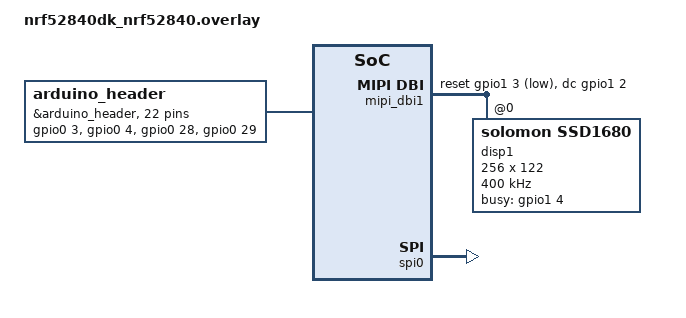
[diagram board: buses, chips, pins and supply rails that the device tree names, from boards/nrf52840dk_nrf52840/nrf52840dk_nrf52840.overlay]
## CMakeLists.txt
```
cmake_minimum_required(VERSION 3.20.0)
find_package(Zephyr REQUIRED HINTS $ENV{ZEPHYR_BASE})

project(Attempt6WS)

file(GLOB FONT_SOURCES fonts/*.c)

target_sources(app PRIVATE
    src/main.c
    src/fonts5x7.c
    src/fonts_8x12_montserrat.c
    src/mab_labs.c
    src/my_image.c
    ${FONT_SOURCES}
)

target_include_directories(app PRIVATE
  include
)
```

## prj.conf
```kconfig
CONFIG_DISPLAY=y
CONFIG_SSD16XX=y

CONFIG_SPI=y
CONFIG_SPI_NRFX=y

CONFIG_GPIO=y
CONFIG_GPIO_NRFX=y

CONFIG_LOG=y
CONFIG_DISPLAY_LOG_LEVEL_DBG=y
# CONFIG_LOG_BUFFER_SIZE=8192
# CONFIG_LOG_MODE_IMMEDIATE=y


CONFIG_SERIAL=y
CONFIG_UART_CONSOLE=y
CONFIG_CONSOLE=y

# Optional debug
# CONFIG_SSD16XX_LOG_LEVEL_DBG=y
# CONFIG_MIPI_DBI_LOG_LEVEL_DBG=y
# CONFIG_NO_OPTIMIZATIONS=y
# CONFIG_MAIN_STACK_SIZE=31744
```

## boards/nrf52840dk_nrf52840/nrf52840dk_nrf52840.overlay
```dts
/{
    chosen {
        zephyr,display = &disp1;
    };

    mipi_dbi1 {
        compatible = "zephyr,mipi-dbi-spi";
        dc-gpios = <&gpio1 2 GPIO_ACTIVE_HIGH>;
        reset-gpios = <&gpio1 3 GPIO_ACTIVE_LOW>;
        spi-dev = <&spi0>;
        write-only;
        #address-cells = <1>;
        #size-cells = <0>;
        status = "okay";

        disp1: ssd1680@0 {
            compatible = "solomon,ssd1680";
            reg = <0>;
            busy-gpios = <&gpio1 4 (GPIO_PULL_DOWN | GPIO_ACTIVE_HIGH)>;
            width = <256>;
            height = <122>;
            rotation = <0>;
            mipi-max-frequency = <400000>;   
            
            full {};

            // partial {};

            status = "okay";
        };
    };
};


&spi0 {
    status = "okay";
    cs-gpios = <&gpio1 1 GPIO_ACTIVE_LOW>;
};

&gpio1 {
    status = "okay";
};

&arduino_i2c {
    status = "disabled";
};

&arduino_header {
    gpio-map = <0 0 &gpio0 3 0>,
               <1 0 &gpio0 4 0>,
               <2 0 &gpio0 28 0>,
               <3 0 &gpio0 29 0>,
               <4 0 &gpio0 30 0>,
               <5 0 &gpio0 31 0>,
               <6 0 &gpio1 1 0>,
               <7 0 &gpio1 2 0>,
               <8 0 &gpio1 3 0>,
               <9 0 &gpio1 4 0>,
               <10 0 &gpio1 5 0>,
               <11 0 &gpio1 6 0>,
               <12 0 &gpio1 7 0>,
               <13 0 &gpio1 8 0>,
               <14 0 &gpio1 10 0>,
               <15 0 &gpio1 11 0>,
               <16 0 &gpio1 12 0>,
               <17 0 &gpio1 13 0>,
               <18 0 &gpio1 14 0>,
               <19 0 &gpio1 15 0>,
               <20 0 &gpio0 26 0>,
               <21 0 &gpio0 27 0>;
};
```

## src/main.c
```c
#include <zephyr/device.h>
#include <zephyr/devicetree.h>
#include <zephyr/drivers/display.h>
#include <zephyr/drivers/gpio.h>
#include <zephyr/sys/printk.h>
#include <zephyr/logging/log.h>
#include <string.h>
#include <math.h>
#include "fonts5x7.h"
#include "fonts_8x12_montserrat.h"
#include "images.h"

#define DISPLAY_WIDTH      256
#define DISPLAY_HEIGHT     120
#define DISPLAY_PITCH      DISPLAY_WIDTH
#define DISPLAY_BYTE_PITCH ((DISPLAY_WIDTH + 7) / 8)
#define DISPLAY_BUF_SIZE   (DISPLAY_BYTE_PITCH * DISPLAY_HEIGHT)

LOG_MODULE_REGISTER(main);

#define PIXEL_ON 0
#define PIXEL_OFF 1
#define REFRESH_RATE 5000 // milliseconds

static uint8_t raw_buf[DISPLAY_WIDTH * DISPLAY_HEIGHT];  // 1 byte per pixel
static uint8_t buf[DISPLAY_BUF_SIZE];

#pragma region pixel buffer configuration methods

// Set pixel (x,y) to black (0) in the buffer
static void set_pixel(int x, int y) {
    if (x < 0 || x >= DISPLAY_WIDTH || y < 0 || y >= DISPLAY_HEIGHT) {
        return;
    }
    raw_buf[y * DISPLAY_WIDTH + x] = PIXEL_ON;
}

static void color_off(int x, int y) {
    if (x < 0 || x >= DISPLAY_WIDTH || y < 0 || y >= DISPLAY_HEIGHT) {
        return;
    }
    raw_buf[y * DISPLAY_WIDTH + x] = PIXEL_OFF;
}

// Fills buffer
static void pack_buffer(void) {
    memset(buf, 0xFF, sizeof(buf));  // Set all to white
    for (int y = 0; y < DISPLAY_HEIGHT; y++) {
        for (int x = 0; x < DISPLAY_WIDTH; x++) {
            if (raw_buf[y * DISPLAY_WIDTH + x] == PIXEL_ON) {
                int byte_index = x + (y / 8) * DISPLAY_WIDTH;
                int bit_pos = 7 - (y % 8);
                buf[byte_index] &= ~(1 << bit_pos);
                // Uncomment to debug:
                // LOG_INF("PACK: (x=%d y=%d) -> Byte %d, bit %d", x, y, byte_index, bit_pos);
            }
        }
    }
}

#pragma endregion

#pragma region 5x7_mono text
static void draw_char_5x7(int x, int y, char c) {
    const uint8_t *bitmap = NULL;

    if (c < 0x20 || c > 0x7E) {
        c = ' ';
    }

    const uint8_t *glyph = font5x7[c - 0x20];

    for (int col = 0; col < 5; col++) {
        uint8_t bits = glyph[col];
        for (int row = 0; row < 7; row++) {
            if (bits & (1 << row)) {
                set_pixel(x + col, y + row);
            }
        }
    }
}

static void draw_string_5x7(int x, int y, const char *str) {
    while (*str) {
        draw_char_5x7(x, y, *str);
        x += 6;  // 5 columns + 1 space
        str++;
    }
}

// void draw_string_5x7_test() {
//     draw_string_5x7(10, 10, " !\"#$%&'()*+,-./012");
//     draw_string_5x7(10, 30, "3456789:;<=>?@ABCDE");
//     draw_string_5x7(10, 50, "FGHIJKLMNOPQRSTUVWX");
//     draw_string_5x7(10, 70, "YZ[\\]^_`abcdefghijk");
//     draw_string_5x7(10, 90, "lmnopqrstuvwxyz{|}~");
// }

#pragma endregion

#pragma region 8x12_montserrat text

static void draw_char_8x12_montserrat(int x, int y, char c) {
    if (c < 0x20 || c > 0x7E) {
        return; // unsupported character
    }

    const uint8_t *glyph = font_8x12_montserrat[c - 0x20];

    for (int row = 0; row < 12; row++) {
        uint8_t row_bits = glyph[row];  // 8 pixels horizontally

        for (int col = 0; col < 8; col++) {
            if (row_bits & (1 << (7 - col))) {
                set_pixel(x + col, y + row); // (x, y) is top-left of char
            }
        }
    }
}

static void draw_string_8x12_montserrat(int x, int y, const char *str) {
    while (*str) {
        draw_char_8x12_montserrat(x, y, *str);
        x += 9;
        str++;
    }
}

// void draw_string_8x12_test() {
//     draw_string_8x12(10, 10, " !\"#$%&'()*+,-./012");
//     draw_string_8x12(10, 30, "3456789:;<=>?@ABCDE");
//     draw_string_8x12(10, 50, "FGHIJKLMNOPQRSTUVWX");
//     draw_string_8x12(10, 70, "YZ[\\]^_`abcdefghijk");
//     draw_string_8x12(10, 90, "lmnopqrstuvwxyz{|}~");
// }

#pragma endregion

#pragma region image

void draw_my_image(const Image *img, int x_offset, int y_offset) {
    int width = img->width;
    int height = img->height;
    int bytes_per_row = img->bytes_per_row;

    for (int y = 0; y < height; y++) {
        for (int byte_index = 0; byte_index < bytes_per_row; byte_index++) {
            uint8_t byte = img->data[y * bytes_per_row + byte_index];
            for (int bit = 0; bit < 8; bit++) {
                int x = byte_index * 8 + bit;
                if (x >= width) break;  // Ignore bits outside width

                // Check if bit is set (pixel on)
                if (byte & (0x80 >> bit)) {
                    set_pixel(x + x_offset, y + y_offset);
                }
            }
        }
    }
}

#pragma endregion

#pragma region pattern methods

void pattern_checkerboard(void) {
    for (int y = 0; y < DISPLAY_HEIGHT; y++) {
        for (int x = 0; x < DISPLAY_WIDTH; x++) {
            if ((x + y) % 2 == 0) set_pixel(x, y);
        }
    }
}

void pattern_big_checkerboard(void) {
    int block_size = 8;
    for (int y = 0; y < DISPLAY_HEIGHT; y++) {
        for (int x = 0; x < DISPLAY_WIDTH; x++) {
            int block_x = x / block_size;
            int block_y = y / block_size;
            if ((block_x + block_y) % 2 == 0) set_pixel(x, y);
        }
    }
}

void pattern_bigger_checkerboard(void) {
    int block_size = 16;
    for (int y = 0; y < DISPLAY_HEIGHT; y++) {
        for (int x = 0; x < DISPLAY_WIDTH; x++) {
            int block_x = x / block_size;
            int block_y = y / block_size;
            if ((block_x + block_y) % 2 == 0) set_pixel(x, y);
        }
    }
}

void pattern_gigantic_checkerboard(void) {
    int block_size = 32;
    for (int y = 0; y < DISPLAY_HEIGHT; y++) {
        for (int x = 0; x < DISPLAY_WIDTH; x++) {
            int block_x = x / block_size;
            int block_y = y / block_size;
            if ((block_x + block_y) % 2 == 0) set_pixel(x, y);
        }
    }
}

void pattern_grid(void) {
    for (int y = 0; y < DISPLAY_HEIGHT; y += 8) {
        for (int x = 0; x < DISPLAY_WIDTH; x++) set_pixel(x, y);
    }
    for (int x = 0; x < DISPLAY_WIDTH; x += 8) {
        for (int y = 0; y < DISPLAY_HEIGHT; y++) set_pixel(x, y);
    }
}

void pattern_concentric_squares(void) {
    for (int layer = 0; layer < DISPLAY_HEIGHT / 2; layer += 8) {
        for (int x = layer; x < DISPLAY_WIDTH - layer; x++) {
            set_pixel(x, layer);
            set_pixel(x, DISPLAY_HEIGHT - 1 - layer);
        }
        for (int y = layer; y < DISPLAY_HEIGHT - layer; y++) {
            set_pixel(layer, y);
            set_pixel(DISPLAY_WIDTH - 1 - layer, y);
        }
    }
}

void pattern_polka_dots(void) {
    const int dot_spacing_x = 16, dot_spacing_y = 16, dot_radius = 2;
    for (int cy = dot_radius; cy < DISPLAY_HEIGHT; cy += dot_spacing_y) {
        for (int cx = dot_radius; cx < DISPLAY_WIDTH; cx += dot_spacing_x) {
            for (int y = -dot_radius; y <= dot_radius; y++) {
                for (int x = -dot_radius; x <= dot_radius; x++) {
                    if (x * x + y * y <= dot_radius * dot_radius) {
                        set_pixel(cx + x, cy + y);
                    }
                }
            }
        }
    }
}

void pattern_radial_stripes(void) {
    double M_PI = 3.14159265358979323846;
    int cx = DISPLAY_WIDTH / 2, cy = DISPLAY_HEIGHT / 2;
    for (int y = 0; y < DISPLAY_HEIGHT; y++) {
        for (int x = 0; x < DISPLAY_WIDTH; x++) {
            int dx = x - cx, dy = y - cy;
            float angle = atan2f(dy, dx);
            if (((int)((angle + M_PI) / (M_PI / 8))) % 2 == 0) {
                set_pixel(x, y);
            }
        }
    }
}

void pattern_spiral(void) {
    int cx = DISPLAY_WIDTH / 2;
    int cy = DISPLAY_HEIGHT / 2;
    float k = 10.0f;           // Spiral tightness (higher = tighter spiral)
    float band_width = 6.0f;   // Width of each spiral arm
    float r_min = 4.0f;        // Minimum radius to start drawing (avoids center blob)

    for (int y = 0; y < DISPLAY_HEIGHT; y++) {
        for (int x = 0; x < DISPLAY_WIDTH; x++) {
            int dx = x - cx;
            int dy = y - cy;
            float r = sqrtf(dx * dx + dy * dy);

            if (r < r_min) {
                continue; // Skip drawing near the center to avoid the dark spot
            }

            float angle = atan2f(dy, dx); // Range: -π to π
            float spiral_r = k * angle;

            float dist = r - spiral_r;

            if (fmodf(dist + band_width, band_width * 2.0f) < band_width) {
                set_pixel(x, y);
            }
        }
    }
}

void pattern_concentric_circles(void) {
    int cx = DISPLAY_WIDTH / 2, cy = DISPLAY_HEIGHT / 2;
    for (int y = 0; y < DISPLAY_HEIGHT; y++) {
        for (int x = 0; x < DISPLAY_WIDTH; x++) {
            int dx = x - cx, dy = y - cy;
            int r = (int)sqrtf(dx * dx + dy * dy);
            if ((r / 5) % 2 == 0) set_pixel(x, y);
        }
    }
}

void pattern_mab_labs(void) {
    draw_string_5x7(10, 10, "Interns");
    draw_string_5x7(10, 30, "at Mab-labs");
    draw_string_5x7(10, 50, "present --->");

    // ONLY LOOKS NICE WITH THE MAB-LABS logo or any 120x120 image 
    draw_my_image(&mab_labs, (DISPLAY_WIDTH / 2) - 30, (DISPLAY_HEIGHT / 2) - 60);
}

#pragma endregion


// Method that shows every programmed pattern in an infinite loop
void show_patterns_loop(const struct device *display_dev, struct display_buffer_descriptor *desc) {
    typedef void (*pattern_func_t)(void);
    pattern_func_t patterns[] = {
        pattern_checkerboard,
        pattern_big_checkerboard,
        pattern_bigger_checkerboard,
        pattern_gigantic_checkerboard,
        pattern_grid,
        pattern_concentric_squares,
        pattern_polka_dots,
        pattern_radial_stripes,
        pattern_spiral,
        pattern_concentric_circles,
        pattern_mab_labs,
    };
    const int pattern_count = sizeof(patterns) / sizeof(patterns[0]);

    while (1) {
        for (int i = 0; i < pattern_count; i++) {
            memset(raw_buf, 1, sizeof(raw_buf));  // Clear to white
            patterns[i]();
            pack_buffer();
            display_write(display_dev, 0, 0, desc, buf);
            if(display_write(display_dev, 0, 0, &desc, buf) != 0) {
                LOG_ERR("display_write failed (%d)");
            }
            k_msleep(REFRESH_RATE);
        }
    }
}


int main(void)
{

#pragma region setup
    const struct device *display_dev = DEVICE_DT_GET(DT_CHOSEN(zephyr_display));
    const struct device *reset_dev   = device_get_binding("GPIO_1");
    const struct device *spi_dev     = DEVICE_DT_GET(DT_NODELABEL(spi0));
    const struct device *gpio_dev    = DEVICE_DT_GET(DT_NODELABEL(gpio1));

    if (reset_dev) {
        gpio_pin_configure(reset_dev, 3, GPIO_OUTPUT);
        gpio_pin_set(reset_dev, 3, 0);
        k_sleep(K_MSEC(10));
        gpio_pin_set(reset_dev, 3, 1);
        k_sleep(K_MSEC(10));
    }

    LOG_INF("SPI ready? %d", device_is_ready(spi_dev));
    LOG_INF("GPIO1 ready? %d", device_is_ready(gpio_dev));
    LOG_INF("Chosen display node: %s", DT_NODE_FULL_NAME(DT_CHOSEN(zephyr_display)));

    LOG_INF("Delaying for display power up");
    k_msleep(100);

    if (!device_is_ready(display_dev)) {
        LOG_ERR("Display device not ready");
        return -1;
    }

    LOG_INF("DEVICE IS READY!!!");
    LOG_INF("Display device name: %s", display_dev->name);

#pragma endregion

    display_blanking_off(display_dev);
    memset(raw_buf, 1, sizeof(raw_buf));  // White pixels

    // buffer that will be programmed through pattern methods and passed to be written to ePaper
    struct display_buffer_descriptor desc = {
        .width = DISPLAY_WIDTH,
        .height = DISPLAY_HEIGHT,
        .pitch = DISPLAY_PITCH,
        .buf_size = DISPLAY_BUF_SIZE,
    };

    show_patterns_loop(display_dev, &desc);    

    // draw_my_image(&my_image, 0, 0);
    // int x_displacement = 70;
    // draw_string_5x7(x_displacement, 30, "\"Without math,");
    // draw_string_5x7(x_displacement, 38, " we're dead in");
    // draw_string_5x7(x_displacement, 46, " the water\"");
    // draw_string_5x7(x_displacement + 10, 60, "- Ken Chung");

    // pack_buffer();
    display_write(display_dev, 0, 0, &desc, buf);

    k_msleep(1000);

    while (1) {
        k_sleep(K_SECONDS(30));
    }

    return 0;
}
```

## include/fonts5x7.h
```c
#ifndef FONTS5X7_H
#define FONTS5X7_H

#include <stdint.h>

#ifdef __cplusplus
extern "C" {
#endif

// 5x7 font array: printable ASCII 0x20 (space) to 0x7F (~)
// Each char is 5 bytes (columns)
extern const uint8_t font5x7[95][5];

#ifdef __cplusplus
}
#endif

#endif // FONTS5X7_H
```

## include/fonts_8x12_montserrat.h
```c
#ifndef FONTS8X12_MONTSERRAT_H
#define FONTS8X12_MONTSERRAT_H

#include <stdint.h>

#ifdef __cplusplus
extern "C" {
#endif

// 8x12 Montserrat font array: printable ASCII 0x30 ('0') to 0x5A ('Z')
// Each char is 12 bytes (rows), 8 pixels wide
// Characters included: '0'..'9', 'A'..'Z' (total 10 + 26 = 36 glyphs)
extern const uint8_t font_8x12_montserrat[95][12];

#ifdef __cplusplus
}
#endif

#endif // FONTS8X12_MONTSERRAT_H
```

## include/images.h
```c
#ifndef MY_IMAGE_H
#define MY_IMAGE_H

#include <stdint.h>

#ifdef __cplusplus
extern "C" {
#endif

// Image metadata + pixel data container
typedef struct {
    uint16_t width;         // in pixels
    uint16_t height;        // in pixels
    const uint8_t *data;    // pointer to packed 1bpp pixel data
    uint8_t bytes_per_row;
} Image;

extern const Image my_image;
extern const uint8_t my_image_data[];

extern const Image mab_labs;
extern const uint8_t mab_labs_data[];


#ifdef __cplusplus
}
#endif

#endif // MY_IMAGE_H
```

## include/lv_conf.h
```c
#ifndef LV_CONF_H
#define LV_CONF_H

#define LV_HOR_RES_MAX 250
#define LV_VER_RES_MAX 122
#define LV_COLOR_DEPTH 1
#define LV_USE_LOG 1

#endif
```

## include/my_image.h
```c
#ifndef MY_IMAGE_H
#define MY_IMAGE_H

#include <stdint.h>

#ifdef __cplusplus
extern "C" {
#endif

#define MY_IMAGE_WIDTH 120
#define MY_IMAGE_HEIGHT 120

// 1-bit-per-pixel packed bitmap image
extern const uint8_t my_image_data[];

#ifdef __cplusplus
}
#endif

#endif // MY_IMAGE_H
```

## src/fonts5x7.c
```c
#include "fonts5x7.h"

const uint8_t font5x7[95][5] = {
    // SPACE (0x20)
    {0x00, 0x00, 0x00, 0x00, 0x00},

    // !
    {0x00, 0x00, 0x5F, 0x00, 0x00},
    
    // "
    {0x00, 0x07, 0x00, 0x07, 0x00},
    
    // #
    {0x14, 0x7F, 0x14, 0x7F, 0x14},
    
    // $
    {0x24, 0x2A, 0x7F, 0x2A, 0x12},
    
    // %
    {0x23, 0x13, 0x08, 0x64, 0x62},
    
    // &
    {0x36, 0x49, 0x55, 0x22, 0x50},
    
    // '
    {0x00, 0x05, 0x03, 0x00, 0x00},
    
    // (
    {0x00, 0x1C, 0x22, 0x41, 0x00},
    
    // )
    {0x00, 0x41, 0x22, 0x1C, 0x00},
    
    // *
    {0x14, 0x08, 0x3E, 0x08, 0x14},
    
    // +
    {0x08, 0x08, 0x3E, 0x08, 0x08},
    
    // ,
    {0x00, 0x50, 0x30, 0x00, 0x00},
    
    // -
    {0x08, 0x08, 0x08, 0x08, 0x08},
    
    // .
    {0x00, 0x60, 0x60, 0x00, 0x00},
    
    // /
    {0x20, 0x10, 0x08, 0x04, 0x02},

    // 0
    {0x3E, 0x51, 0x49, 0x45, 0x3E},
    
    // 1
    {0x00, 0x42, 0x7F, 0x40, 0x00},
    
    // 2
    {0x42, 0x61, 0x51, 0x49, 0x46},
    
    // 3
    {0x21, 0x41, 0x45, 0x4B, 0x31},
    
    // 4
    {0x18, 0x14, 0x12, 0x7F, 0x10},
    
    // 5
    {0x27, 0x45, 0x45, 0x45, 0x39},
    
    // 6
    {0x3C, 0x4A, 0x49, 0x49, 0x30},
    
    // 7
    {0x01, 0x71, 0x09, 0x05, 0x03},
    
    // 8
    {0x36, 0x49, 0x49, 0x49, 0x36},
    
    // 9
    {0x06, 0x49, 0x49, 0x29, 0x1E},
    
    // :
    {0x00, 0x36, 0x36, 0x00, 0x00},
    
    // ;
    {0x00, 0x56, 0x36, 0x00, 0x00},
    
    // <
    {0x08, 0x14, 0x22, 0x41, 0x00},
    
    // =
    {0x14, 0x14, 0x14, 0x14, 0x14},
    
    // >
    {0x00, 0x41, 0x22, 0x14, 0x08},
    
    // ?
    {0x02, 0x01, 0x51, 0x09, 0x06},
    
    // @
    {0x32, 0x49, 0x79, 0x41, 0x3E},
    
    // A
    {0x7E, 0x11, 0x11, 0x11, 0x7E},
    
    // B
    {0x7F, 0x49, 0x49, 0x49, 0x36},
    
    // C
    {0x3E, 0x41, 0x41, 0x41, 0x22},
    
    // D
    {0x7F, 0x41, 0x41, 0x22, 0x1C},
    
    // E
    {0x7F, 0x49, 0x49, 0x49, 0x41},
    
    // F
    {0x7F, 0x09, 0x09, 0x09, 0x01},
    
    // G
    {0x3E, 0x41, 0x49, 0x49, 0x7A},
    
    // H
    {0x7F, 0x08, 0x08, 0x08, 0x7F},
    
    // I
    {0x00, 0x41, 0x7F, 0x41, 0x00},
    
    // J
    {0x20, 0x40, 0x41, 0x3F, 0x01},
    
    // K
    {0x7F, 0x08, 0x14, 0x22, 0x41},
    
    // L
    {0x7F, 0x40, 0x40, 0x40, 0x40},
    
    // M
    {0x7F, 0x02, 0x04, 0x02, 0x7F},
    
    // N
    {0x7F, 0x04, 0x08, 0x10, 0x7F},
    
    // O
    {0x3E, 0x41, 0x41, 0x41, 0x3E},
    
    // P
    {0x7F, 0x09, 0x09, 0x09, 0x06},
    
    // Q
    {0x3E, 0x41, 0x51, 0x21, 0x5E},
    
    // R
    {0x7F, 0x09, 0x19, 0x29, 0x46},
    
    // S
    {0x46, 0x49, 0x49, 0x49, 0x31},
    
    // T
    {0x01, 0x01, 0x7F, 0x01, 0x01},
    
    // U
    {0x3F, 0x40, 0x40, 0x40, 0x3F},
    
    // V
    {0x1F, 0x20, 0x40, 0x20, 0x1F},
    
    // W
    {0x7F, 0x20, 0x18, 0x20, 0x7F},
    
    // X
    {0x63, 0x14, 0x08, 0x14, 0x63},
    
    // Y
    {0x03, 0x04, 0x78, 0x04, 0x03},
    
    // Z
    {0x61, 0x51, 0x49, 0x45, 0x43},
    
    // [
    {0x00, 0x7F, 0x41, 0x41, 0x00},
    
    // \ backslash
    {0x02, 0x04, 0x08, 0x10, 0x20},
    
    // ]
    {0x00, 0x41, 0x41, 0x7F, 0x00},
    
    // ^
    {0x04, 0x02, 0x01, 0x02, 0x04},
    
    // _
    {0x40, 0x40, 0x40, 0x40, 0x40},
    
    // `
    {0x00, 0x01, 0x02, 0x04, 0x00},
    
    // a
    {0x20, 0x54, 0x54, 0x54, 0x78},
    
    // b
    {0x7F, 0x48, 0x44, 0x44, 0x38},
    
    // c
    {0x38, 0x44, 0x44, 0x44, 0x20},
    
    // d
    {0x38, 0x44, 0x44, 0x48, 0x7F},
    
    // e
    {0x38, 0x54, 0x54, 0x54, 0x18},
    
    // f
    {0x08, 0x7E, 0x09, 0x01, 0x02},
    
    // g
    {0x0C, 0x52, 0x52, 0x52, 0x3E},
    
    // h
    {0x7F, 0x08, 0x04, 0x04, 0x78},
    
    // i
    {0x00, 0x44, 0x7D, 0x40, 0x00},
    
    // j
    {0x20, 0x40, 0x44, 0x3D, 0x00},
    
    // k
    {0x7F, 0x10, 0x28, 0x44, 0x00},
    
    // l
    {0x00, 0x41, 0x7F, 0x40, 0x00},
    
    // m
    {0x7C, 0x04, 0x18, 0x04, 0x78},
    
    // n
    {0x7C, 0x08, 0x04, 0x04, 0x78},
    
    // o
    {0x38, 0x44, 0x44, 0x44, 0x38},
    
    // p
    {0x7C, 0x14, 0x14, 0x14, 0x08},
    
    // q
    {0x08, 0x14, 0x14, 0x18, 0x7C},
    
    // r
    {0x7C, 0x08, 0x04, 0x04, 0x08},
    
    // s
    {0x48, 0x54, 0x54, 0x54, 0x20},
    
    // t
    {0x04, 0x3F, 0x44, 0x40, 0x20},
    
    // u
    {0x3C, 0x40, 0x40, 0x20, 0x7C},
    
    // v
    {0x1C, 0x20, 0x40, 0x20, 0x1C},
    
    // w
    {0x3C, 0x40, 0x30, 0x40, 0x3C},
    
    // x
    {0x44, 0x28, 0x10, 0x28, 0x44},
    
    // y
    {0x0C, 0x50, 0x50, 0x50, 0x3C},
    
    // z
    {0x44, 0x64, 0x54, 0x4C, 0x44},

    // {
    {0x00, 0x08, 0x36, 0x41, 0x00},
    
    // |
    {0x00, 0x00, 0x7F, 0x00, 0x00},
    
    // }
    {0x00, 0x41, 0x36, 0x08, 0x00},
    
    // ~
    {0x02, 0x01, 0x02, 0x04, 0x02},

};
```

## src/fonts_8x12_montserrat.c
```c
#include "fonts_8x12_montserrat.h"

const uint8_t font_8x12_montserrat[95][12] = {
    // ' ' (space)
    {0x00, 0x00, 0x00, 0x00, 0x00, 0x00, 0x00, 0x00, 0x00, 0x00, 0x00, 0x00},

    // '!' 0x21
    {0x10, 0x10, 0x10, 0x10, 0x10, 0x10, 0x00, 0x00, 0x10, 0x00, 0x00, 0x00},

    // '"' 0x22
    {0x28, 0x28, 0x28, 0x00, 0x00, 0x00, 0x00, 0x00, 0x00, 0x00, 0x00, 0x00},

    // '#' 0x23
    {0x28, 0x28, 0x7C, 0x28, 0x28, 0x7C, 0x28, 0x28, 0x00, 0x00, 0x00, 0x00},

    // '$' 0x24
    {0x10, 0x3E, 0x50, 0x3C, 0x12, 0x7C, 0x10, 0x10, 0x00, 0x00, 0x00, 0x00},

    // '%' 0x25
    {0x60, 0x64, 0x08, 0x10, 0x20, 0x4C, 0x4C, 0x00, 0x00, 0x00, 0x00, 0x00},

    // '&' 0x26
    {0x30, 0x48, 0x50, 0x30, 0x56, 0x4A, 0x34, 0x00, 0x00, 0x00, 0x00, 0x00},

    // ''' 0x27 (single quote)
    {0x10, 0x10, 0x20, 0x00, 0x00, 0x00, 0x00, 0x00, 0x00, 0x00, 0x00, 0x00},

    // '(' 0x28
    {0x08, 0x10, 0x20, 0x20, 0x20, 0x20, 0x10, 0x08, 0x00, 0x00, 0x00, 0x00},

    // ')' 0x29
    {0x20, 0x10, 0x08, 0x08, 0x08, 0x08, 0x10, 0x20, 0x00, 0x00, 0x00, 0x00},

    // '*' 0x2A
    {0x00, 0x28, 0x10, 0x7C, 0x10, 0x28, 0x00, 0x00, 0x00, 0x00, 0x00, 0x00},

    // '+' 0x2B
    {0x00, 0x10, 0x10, 0x7C, 0x10, 0x10, 0x00, 0x00, 0x00, 0x00, 0x00, 0x00},

    // ',' 0x2C
    {0x00, 0x00, 0x00, 0x00, 0x00, 0x30, 0x30, 0x20, 0x00, 0x00, 0x00, 0x00},

    // '-' 0x2D
    {0x00, 0x00, 0x00, 0x7C, 0x00, 0x00, 0x00, 0x00, 0x00, 0x00, 0x00, 0x00},

    // '.' 0x2E
    {0x00, 0x00, 0x00, 0x00, 0x00, 0x30, 0x30, 0x00, 0x00, 0x00, 0x00, 0x00},

    // '/' 0x2F
    {0x00, 0x04, 0x08, 0x10, 0x20, 0x40, 0x00, 0x00, 0x00, 0x00, 0x00, 0x00},

    // '0' 0x30
    {0x3C, 0x42, 0x81, 0x81, 0x81, 0x81, 0x81, 0x81, 0x42, 0x3C, 0x00, 0x00},

    // '1' 0x31
    {0x10, 0x30, 0x50, 0x10, 0x10, 0x10, 0x10, 0x10, 0x7C, 0x00, 0x00, 0x00},

    // '2' 0x32
    {0x3C, 0x42, 0x02, 0x04, 0x08, 0x10, 0x20, 0x40, 0x42, 0x7E, 0x00, 0x00},

    // '3' 0x33
    {0x3C, 0x42, 0x02, 0x1C, 0x02, 0x01, 0x81, 0x81, 0x42, 0x3C, 0x00, 0x00},

    // '4' 0x34
    {0x04, 0x0C, 0x14, 0x24, 0x44, 0x84, 0xFE, 0x04, 0x04, 0x0E, 0x00, 0x00},

    // '5' 0x35
    {0x7E, 0x40, 0x40, 0x7C, 0x02, 0x01, 0x01, 0x81, 0x42, 0x3C, 0x00, 0x00},

    // '6' 0x36
    {0x3C, 0x42, 0x40, 0x7C, 0x42, 0x81, 0x81, 0x81, 0x42, 0x3C, 0x00, 0x00},

    // '7' 0x37
    {0x7E, 0x02, 0x04, 0x08, 0x10, 0x10, 0x10, 0x10, 0x10, 0x10, 0x00, 0x00},

    // '8' 0x38
    {0x3C, 0x42, 0x81, 0x42, 0x3C, 0x42, 0x81, 0x81, 0x42, 0x3C, 0x00, 0x00},

    // '9' 0x39
    {0x3C, 0x42, 0x81, 0x81, 0x43, 0x3D, 0x01, 0x42, 0x3C, 0x00, 0x00, 0x00},

    // ':' 0x3A
    {0x00, 0x30, 0x30, 0x00, 0x00, 0x00, 0x00, 0x30, 0x30, 0x00, 0x00, 0x00},

    // ';' 0x3B
    {0x00, 0x30, 0x30, 0x00, 0x00, 0x00, 0x00, 0x30, 0x30, 0x20, 0x00, 0x00},

    // '<' 0x3C
    {0x08, 0x10, 0x20, 0x40, 0x20, 0x10, 0x08, 0x00, 0x00, 0x00, 0x00, 0x00},

    // '=' 0x3D
    {0x00, 0x00, 0x7E, 0x00, 0x00, 0x7E, 0x00, 0x00, 0x00, 0x00, 0x00, 0x00},

    // '>' 0x3E
    {0x20, 0x10, 0x08, 0x04, 0x08, 0x10, 0x20, 0x00, 0x00, 0x00, 0x00, 0x00},

    // '?' 0x3F
    {0x3C, 0x42, 0x02, 0x04, 0x08, 0x10, 0x10, 0x00, 0x10, 0x00, 0x00, 0x00},

    // '@' 0x40
    {0x3C, 0x42, 0x99, 0xA5, 0xA5, 0x9D, 0x81, 0x42, 0x3C, 0x00, 0x00, 0x00},

    // 'A' 0x41
    {0x10, 0x28, 0x28, 0x44, 0x44, 0x7C, 0x82, 0x82, 0x82, 0x00, 0x00, 0x00},

    // 'B' 0x42
    {0xF8, 0x44, 0x44, 0x78, 0x44, 0x44, 0xF8, 0x00, 0x00, 0x00, 0x00, 0x00},

    // 'C' 0x43
    {0x3C, 0x42, 0x80, 0x80, 0x80, 0x80, 0x42, 0x3C, 0x00, 0x00, 0x00, 0x00},

    // 'D' 0x44
    {0xF0, 0x48, 0x44, 0x44, 0x44, 0x48, 0xF0, 0x00, 0x00, 0x00, 0x00, 0x00},

    // 'E' 0x45
    {0x7C, 0x40, 0x40, 0x78, 0x40, 0x40, 0x7C, 0x00, 0x00, 0x00, 0x00, 0x00},

    // 'F' 0x46
    {0x7C, 0x40, 0x40, 0x78, 0x40, 0x40, 0x40, 0x00, 0x00, 0x00, 0x00, 0x00},

    // 'G' 0x47
    {0x3C, 0x42, 0x80, 0x80, 0x9E, 0x82, 0x42, 0x3C, 0x00, 0x00, 0x00, 0x00},

    // 'H' 0x48
    {0x82, 0x82, 0x82, 0xFE, 0x82, 0x82, 0x82, 0x00, 0x00, 0x00, 0x00, 0x00},

    // 'I' 0x49
    {0x7C, 0x10, 0x10, 0x10, 0x10, 0x10, 0x7C, 0x00, 0x00, 0x00, 0x00, 0x00},

    // 'J' 0x4A
    {0x3E, 0x04, 0x04, 0x04, 0x84, 0x84, 0x48, 0x30, 0x00, 0x00, 0x00, 0x00},

    // 'K' 0x4B
    {0x82, 0x84, 0x88, 0xF0, 0x88, 0x84, 0x82, 0x00, 0x00, 0x00, 0x00, 0x00},

    // 'L' 0x4C
    {0x80, 0x80, 0x80, 0x80, 0x80, 0x80, 0xFC, 0x00, 0x00, 0x00, 0x00, 0x00},

    // 'M' 0x4D
    {0x82, 0xC6, 0xAA, 0x92, 0x82, 0x82, 0x82, 0x00, 0x00, 0x00, 0x00, 0x00},

    // 'N' 0x4E
    {0x82, 0xC2, 0xA2, 0x92, 0x8A, 0x86, 0x82, 0x00, 0x00, 0x00, 0x00, 0x00},

    // 'O' 0x4F
    {0x3C, 0x42, 0x81, 0x81, 0x81, 0x81, 0x42, 0x3C, 0x00, 0x00, 0x00, 0x00},

    // 'P' 0x50
    {0xFC, 0x82, 0x82, 0xFC, 0x80, 0x80, 0x80, 0x00, 0x00, 0x00, 0x00, 0x00},

    // 'Q' 0x51
    {0x3C, 0x42, 0x81, 0x81, 0x81, 0x91, 0x4A, 0x3C, 0x06, 0x00, 0x00, 0x00},

    // 'R' 0x52
    {0xFC, 0x82, 0x82, 0xFC, 0x90, 0x88, 0x84, 0x00, 0x00, 0x00, 0x00, 0x00},

    // 'S' 0x53
    {0x3E, 0x40, 0x40, 0x3C, 0x02, 0x02, 0xFC, 0x00, 0x00, 0x00, 0x00, 0x00},

    // 'T' 0x54
    {0x7C, 0x10, 0x10, 0x10, 0x10, 0x10, 0x10, 0x00, 0x00, 0x00, 0x00, 0x00},

    // 'U' 0x55
    {0x82, 0x82, 0x82, 0x82, 0x82, 0x82, 0x7C, 0x00, 0x00, 0x00, 0x00, 0x00},

    // 'V' 0x56
    {0x82, 0x82, 0x82, 0x44, 0x44, 0x28, 0x10, 0x00, 0x00, 0x00, 0x00, 0x00},

    // 'W' 0x57
    {0x82, 0x82, 0x82, 0x92, 0xAA, 0xC6, 0x82, 0x00, 0x00, 0x00, 0x00, 0x00},

    // 'X' 0x58
    {0x82, 0x44, 0x28, 0x10, 0x28, 0x44, 0x82, 0x00, 0x00, 0x00, 0x00, 0x00},

    // 'Y' 0x59
    {0x82, 0x44, 0x28, 0x10, 0x10, 0x10, 0x10, 0x00, 0x00, 0x00, 0x00, 0x00},

    // 'Z' 0x5A
    {0xFE, 0x02, 0x04, 0x08, 0x10, 0x20, 0x40, 0xFE, 0x00, 0x00, 0x00, 0x00},

    // '[' 0x5B
    {0x3C, 0x20, 0x20, 0x20, 0x20, 0x20, 0x20, 0x20, 0x3C, 0x00, 0x00, 0x00},

    // '\' 0x5C
    {0x80, 0x40, 0x40, 0x20, 0x20, 0x10, 0x10, 0x08, 0x08, 0x04, 0x00, 0x00},

    // ']' 0x5D
    {0x3C, 0x04, 0x04, 0x04, 0x04, 0x04, 0x04, 0x04, 0x3C, 0x00, 0x00, 0x00},

    // '^' 0x5E
    {0x10, 0x28, 0x44, 0x82, 0x00, 0x00, 0x00, 0x00, 0x00, 0x00, 0x00, 0x00},

    // '_' 0x5F
    {0x00, 0x00, 0x00, 0x00, 0x00, 0x00, 0x00, 0x00, 0x00, 0x00, 0xFF, 0x00},

    // '`' 0x60
    {0x20, 0x10, 0x08, 0x00, 0x00, 0x00, 0x00, 0x00, 0x00, 0x00, 0x00, 0x00},

    // 'a' 0x61
    {0x00, 0x00, 0x00, 0x3C, 0x42, 0x3E, 0x42, 0x42, 0x3D, 0x00, 0x00, 0x00},

    // 'b' 0x62
    {0x80, 0x80, 0x80, 0xBC, 0xC2, 0x82, 0x82, 0xC2, 0xBC, 0x00, 0x00, 0x00},

    // 'c' 0x63
    {0x00, 0x00, 0x00, 0x3C, 0x42, 0x80, 0x80, 0x42, 0x3C, 0x00, 0x00, 0x00},

    // 'd' 0x64
    {0x02, 0x02, 0x02, 0x3A, 0x46, 0x82, 0x82, 0x46, 0x3A, 0x00, 0x00, 0x00},

    // 'e' 0x65
    {0x00, 0x00, 0x00, 0x3C, 0x42, 0xFE, 0x80, 0x42, 0x3C, 0x00, 0x00, 0x00},

    // 'f' 0x66
    {0x0E, 0x10, 0x10, 0x7C, 0x10, 0x10, 0x10, 0x10, 0x10, 0x00, 0x00, 0x00},

    // 'g' 0x67
    {0x00, 0x00, 0x00, 0x3A, 0x46, 0x82, 0x82, 0x7E, 0x02, 0x42, 0x3C, 0x00},

    // 'h' 0x68
    {0x80, 0x80, 0x80, 0xBC, 0xC2, 0x82, 0x82, 0x82, 0x82, 0x00, 0x00, 0x00},

    // 'i' 0x69
    {0x10, 0x00, 0x30, 0x10, 0x10, 0x10, 0x10, 0x7C, 0x00, 0x00, 0x00, 0x00},

    // 'j' 0x6A
    {0x04, 0x00, 0x1C, 0x08, 0x08, 0x08, 0x08, 0x88, 0x88, 0x70, 0x00, 0x00},

    // 'k' 0x6B
    {0x80, 0x80, 0x80, 0x84, 0x88, 0xF0, 0x88, 0x84, 0x82, 0x00, 0x00, 0x00},

    // 'l' 0x6C
    {0x30, 0x10, 0x10, 0x10, 0x10, 0x10, 0x10, 0x7C, 0x00, 0x00, 0x00, 0x00},

    // 'm' 0x6D
    {0x00, 0x00, 0x00, 0xEC, 0x92, 0x92, 0x92, 0x92, 0x92, 0x00, 0x00, 0x00},

    // 'n' 0x6E
    {0x00, 0x00, 0x00, 0xBC, 0xC2, 0x82, 0x82, 0x82, 0x82, 0x00, 0x00, 0x00},

    // 'o' 0x6F
    {0x00, 0x00, 0x00, 0x3C, 0x42, 0x81, 0x81, 0x42, 0x3C, 0x00, 0x00, 0x00},

    // 'p' 0x70
    {0x00, 0x00, 0x00, 0xBC, 0xC2, 0x82, 0x82, 0xC2, 0xBC, 0x80, 0x80, 0x00},

    // 'q' 0x71
    {0x00, 0x00, 0x00, 0x3A, 0x46, 0x82, 0x82, 0x46, 0x3A, 0x02, 0x02, 0x00},

    // 'r' 0x72
    {0x00, 0x00, 0x00, 0x5C, 0x62, 0x40, 0x40, 0x40, 0x40, 0x00, 0x00, 0x00},

    // 's' 0x73
    {0x00, 0x00, 0x00, 0x3E, 0x40, 0x3C, 0x02, 0x02, 0xFC, 0x00, 0x00, 0x00},

    // 't' 0x74
    {0x10, 0x10, 0x7C, 0x10, 0x10, 0x10, 0x10, 0x0E, 0x00, 0x00, 0x00, 0x00},

    // 'u' 0x75
    {0x00, 0x00, 0x00, 0x82, 0x82, 0x82, 0x82, 0x46, 0x3A, 0x00, 0x00, 0x00},

    // 'v' 0x76
    {0x00, 0x00, 0x00, 0x82, 0x82, 0x44, 0x44, 0x28, 0x10, 0x00, 0x00, 0x00},

    // 'w' 0x77
    {0x00, 0x00, 0x00, 0x82, 0x92, 0x92, 0xAA, 0x44, 0x44, 0x00, 0x00, 0x00},

    // 'x' 0x78
    {0x00, 0x00, 0x00, 0x82, 0x44, 0x38, 0x28, 0x44, 0x82, 0x00, 0x00, 0x00},

    // 'y' 0x79
    {0x00, 0x00, 0x00, 0x82, 0x82, 0x46, 0x3A, 0x02, 0x42, 0x3C, 0x00, 0x00},

    // 'z' 0x7A
    {0x00, 0x00, 0x00, 0xFE, 0x04, 0x08, 0x10, 0x20, 0xFE, 0x00, 0x00, 0x00},

    // '{' 0x7B
    {0x0C, 0x10, 0x10, 0x10, 0x60, 0x10, 0x10, 0x10, 0x0C, 0x00, 0x00, 0x00},

    // '|' 0x7C
    {0x10, 0x10, 0x10, 0x10, 0x10, 0x10, 0x10, 0x10, 0x10, 0x10, 0x10, 0x10},

    // '}' 0x7D
    {0x60, 0x10, 0x10, 0x10, 0x0C, 0x10, 0x10, 0x10, 0x60, 0x00, 0x00, 0x00},

    // '~' 0x7E
    {0x24, 0x4A, 0x92, 0x00, 0x00, 0x00, 0x00, 0x00, 0x00, 0x00, 0x00, 0x00},

};
```

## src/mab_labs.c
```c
#include "images.h"

#define MY_IMAGE_WIDTH  120
#define MY_IMAGE_HEIGHT 120
#define MY_IMAGE_BYTES_PER_ROW ((MY_IMAGE_WIDTH + 7) / 8)
#define MY_IMAGE_DATA_SIZE (MY_IMAGE_BYTES_PER_ROW * MY_IMAGE_HEIGHT)

const uint8_t mab_labs_data[MY_IMAGE_DATA_SIZE] = {
    // 'test_image', 120x120px
    0x00, 0x00, 0x00, 0x00, 0x00, 0x00, 0x00, 0x00, 0x00, 0x00, 0x00, 0x00, 0x00, 0x00, 0x00, 0x00, 
    0x00, 0x00, 0x00, 0x00, 0x00, 0x00, 0x00, 0x00, 0x00, 0x00, 0x00, 0x00, 0x00, 0x00, 0x00, 0x00, 
    0x00, 0x00, 0x00, 0x00, 0x00, 0x00, 0x00, 0x00, 0x00, 0x00, 0x00, 0x00, 0x00, 0x00, 0x00, 0x00, 
    0x00, 0x00, 0x00, 0x00, 0x00, 0x00, 0x00, 0x00, 0x00, 0x00, 0x00, 0x00, 0x00, 0x00, 0x00, 0x00, 
    0x00, 0x00, 0x00, 0x00, 0x00, 0x00, 0x00, 0x00, 0x00, 0x00, 0x00, 0x00, 0x00, 0x00, 0x00, 0x00, 
    0x00, 0x00, 0x00, 0x00, 0x00, 0x00, 0x00, 0x00, 0x00, 0x00, 0x00, 0x00, 0x00, 0x00, 0x00, 0x00, 
    0x00, 0x00, 0x00, 0x00, 0x00, 0x00, 0x00, 0x00, 0x00, 0x00, 0x00, 0x00, 0x00, 0x00, 0x00, 0x00, 
    0x00, 0x00, 0x00, 0x00, 0x00, 0x00, 0x00, 0x00, 0x00, 0x00, 0x01, 0xc1, 0x81, 0x83, 0xf8, 0x04, 
    0x00, 0xc1, 0xfc, 0x3f, 0x00, 0x00, 0x00, 0x00, 0x00, 0x01, 0xc3, 0xc3, 0xc3, 0xfc, 0x06, 0x01, 
    0xe1, 0xfe, 0x7f, 0x80, 0x00, 0x00, 0x00, 0x00, 0x01, 0xe3, 0xc7, 0xc3, 0xfc, 0x06, 0x01, 0xe1, 
    0xfe, 0x73, 0x80, 0x00, 0x00, 0x00, 0x00, 0x01, 0xe7, 0xc7, 0xc3, 0x0c, 0x06, 0x03, 0xf1, 0x86, 
    0x60, 0x00, 0x00, 0x00, 0x00, 0x00, 0x01, 0xe7, 0xc6, 0x63, 0xfc, 0x06, 0x03, 0x31, 0xfe, 0x7f, 
    0x80, 0x00, 0x00, 0x00, 0x00, 0x01, 0xfe, 0xce, 0x63, 0xfc, 0x06, 0x07, 0x31, 0xfe, 0x7f, 0x80, 
    0x00, 0x00, 0x00, 0x00, 0x01, 0x3c, 0xcf, 0xe3, 0x0c, 0x06, 0x07, 0xf9, 0x87, 0x21, 0x80, 0x00, 
    0x00, 0x00, 0x00, 0x01, 0xbc, 0xcf, 0xf3, 0x0e, 0x06, 0x07, 0xf9, 0x87, 0x61, 0xc0, 0x00, 0x00, 
    0x00, 0x00, 0x01, 0x9c, 0xdc, 0x73, 0xfc, 0x07, 0xfe, 0x39, 0xff, 0x7f, 0x80, 0x00, 0x00, 0x00, 
    0x00, 0x01, 0x98, 0xd8, 0x3b, 0xfc, 0x07, 0xfc, 0x0d, 0xfe, 0x7f, 0x80, 0x00, 0x00, 0x00, 0x00, 
    0x00, 0x00, 0x00, 0x00, 0x00, 0x00, 0x00, 0x00, 0x00, 0x00, 0x00, 0x00, 0x00, 0x00, 0x00, 0x00, 
    0x00, 0x00, 0x00, 0x00, 0x00, 0x00, 0x00, 0x00, 0x00, 0x00, 0x00, 0x00, 0x00, 0x00, 0x00, 0x00, 
    0x00, 0x00, 0x00, 0x00, 0x00, 0x00, 0x00, 0x00, 0x00, 0x00, 0x00, 0x00, 0x00, 0x00, 0x00, 0x00, 
    0x00, 0x00, 0x00, 0x00, 0x00, 0x00, 0x00, 0x00, 0x00, 0x00, 0x00, 0x00, 0x01, 0xff, 0xff, 0x00, 
    0x1f, 0xff, 0xff, 0xff, 0xff, 0xff, 0x00, 0x00, 0x00, 0x00, 0x00, 0x01, 0xff, 0xff, 0x00, 0x3f, 
    0xff, 0xff, 0xff, 0xff, 0xff, 0x80, 0x00, 0x00, 0x00, 0x00, 0x03, 0xff, 0xfe, 0x00, 0x3f, 0xff, 
    0xff, 0xff, 0xff, 0xff, 0x80, 0x00, 0x00, 0x00, 0x00, 0x07, 0xff, 0xfe, 0x00, 0x7f, 0xff, 0xff, 
    0xff, 0xff, 0xff, 0xc0, 0x00, 0x00, 0x00, 0x00, 0x07, 0xff, 0xfc, 0x00, 0xff, 0xff, 0xff, 0xff, 
    0xff, 0xff, 0xe0, 0x00, 0x00, 0x00, 0x00, 0x0f, 0xff, 0xfc, 0x00, 0xff, 0xff, 0xff, 0xff, 0xff, 
    0xff, 0xe0, 0x00, 0x00, 0x00, 0x00, 0x0f, 0xff, 0xf8, 0x01, 0xff, 0xff, 0xff, 0xff, 0xff, 0xff, 
    0xf0, 0x00, 0x00, 0x00, 0x00, 0x1f, 0xff, 0xf0, 0x01, 0xff, 0xff, 0xff, 0xff, 0xff, 0xff, 0xf0, 
    0x00, 0x00, 0x00, 0x00, 0x3f, 0xff, 0xf0, 0x03, 0xff, 0xff, 0xff, 0xff, 0xff, 0xff, 0xf8, 0x00, 
    0x00, 0x00, 0x00, 0x3f, 0xff, 0xe0, 0x03, 0xff, 0xff, 0xff, 0xff, 0xff, 0xff, 0xfc, 0x00, 0x00, 
    0x00, 0x00, 0x7f, 0xff, 0xe0, 0x07, 0xff, 0xff, 0xff, 0xff, 0xff, 0xff, 0xfc, 0x00, 0x00, 0x00, 
    0x00, 0x7f, 0xff, 0xc0, 0x0f, 0xff, 0xff, 0xff, 0xff, 0xff, 0xff, 0xfe, 0x00, 0x00, 0x00, 0x00, 
    0xff, 0xff, 0xc0, 0x0f, 0xff, 0xff, 0xff, 0xff, 0xff, 0xff, 0xfe, 0x00, 0x00, 0x00, 0x00, 0xff, 
    0xff, 0x80, 0x1f, 0xff, 0xff, 0xff, 0xff, 0xff, 0xff, 0xff, 0x00, 0x00, 0x00, 0x01, 0xff, 0xff, 
    0x00, 0x1f, 0xff, 0xff, 0xff, 0xff, 0xff, 0xff, 0xff, 0x00, 0x00, 0x00, 0x03, 0xff, 0xff, 0x00, 
    0x3f, 0xff, 0xe0, 0x00, 0x00, 0x00, 0x7f, 0xff, 0x80, 0x00, 0x00, 0x03, 0xff, 0xfe, 0x00, 0x3f, 
    0xff, 0xe0, 0x00, 0x00, 0x00, 0x7f, 0xff, 0x80, 0x00, 0x00, 0x07, 0xff, 0xfe, 0x00, 0x7f, 0xff, 
    0xc0, 0x00, 0x00, 0x00, 0x3f, 0xff, 0xc0, 0x00, 0x00, 0x07, 0xff, 0xfc, 0x00, 0xff, 0xff, 0xc0, 
    0x00, 0x00, 0x00, 0x3f, 0xff, 0xe0, 0x00, 0x00, 0x0f, 0xff, 0xfc, 0x00, 0xff, 0xff, 0x80, 0x00, 
    0x00, 0x00, 0x1f, 0xff, 0xe0, 0x00, 0x00, 0x0f, 0xff, 0xf8, 0x01, 0xff, 0xff, 0x00, 0x00, 0x00, 
    0x00, 0x0f, 0xff, 0xf0, 0x00, 0x00, 0x1f, 0xff, 0xf0, 0x01, 0xff, 0xff, 0x00, 0x00, 0x00, 0x00, 
    0x0f, 0xff, 0xf8, 0x00, 0x00, 0x3f, 0xff, 0xf0, 0x03, 0xff, 0xfe, 0x00, 0x00, 0x00, 0x00, 0x07, 
    0xff, 0xf8, 0x00, 0x00, 0x3f, 0xff, 0xe0, 0x07, 0xff, 0xfe, 0x00, 0x7f, 0xff, 0xe0, 0x07, 0xff, 
    0xfc, 0x00, 0x00, 0x7f, 0xff, 0xe0, 0x07, 0xff, 0xfc, 0x00, 0x3f, 0xff, 0xe0, 0x03, 0xff, 0xfc, 
    0x00, 0x00, 0x7f, 0xff, 0xc0, 0x0f, 0xff, 0xfc, 0x00, 0x3f, 0xff, 0xf0, 0x01, 0xff, 0xfe, 0x00, 
    0x00, 0xff, 0xff, 0x80, 0x0f, 0xff, 0xf8, 0x00, 0x1f, 0xff, 0xf0, 0x01, 0xff, 0xfe, 0x00, 0x01, 
    0xff, 0xff, 0x80, 0x1f, 0xff, 0xf0, 0x00, 0x1f, 0xff, 0xf8, 0x00, 0xff, 0xff, 0x00, 0x01, 0xff, 
    0xff, 0x00, 0x1f, 0xff, 0xf0, 0x00, 0x0f, 0xff, 0xfc, 0x00, 0xff, 0xff, 0x80, 0x03, 0xff, 0xff, 
    0x00, 0x3f, 0xff, 0xe0, 0x00, 0x07, 0xff, 0xfc, 0x00, 0x7f, 0xff, 0x80, 0x03, 0xff, 0xfe, 0x00, 
    0x3f, 0xff, 0xe0, 0x00, 0x07, 0xff, 0xfe, 0x00, 0x7f, 0xff, 0xc0, 0x07, 0xff, 0xfe, 0x00, 0x7f, 
    0xff, 0xc0, 0x00, 0x03, 0xff, 0xfe, 0x00, 0x3f, 0xff, 0xc0, 0x07, 0xff, 0xfc, 0x00, 0xff, 0xff, 
    0x80, 0x00, 0x03, 0xff, 0xff, 0x00, 0x1f, 0xff, 0xe0, 0x0f, 0xff, 0xf8, 0x00, 0xff, 0xff, 0x80, 
    0x00, 0x01, 0xff, 0xff, 0x80, 0x1f, 0xff, 0xe0, 0x1f, 0xff, 0xf8, 0x01, 0xff, 0xff, 0x00, 0x00, 
    0x01, 0xff, 0xff, 0x80, 0x0f, 0xff, 0xf0, 0x1f, 0xff, 0xf0, 0x01, 0xff, 0xff, 0x00, 0x00, 0x00, 
    0xff, 0xff, 0xc0, 0x0f, 0xff, 0xf8, 0x3f, 0xff, 0xf0, 0x03, 0xff, 0xfe, 0x00, 0x00, 0x00, 0x7f, 
    0xff, 0xc0, 0x07, 0xff, 0xf8, 0x3f, 0xff, 0xe0, 0x07, 0xff, 0xfe, 0x00, 0x00, 0x00, 0x7f, 0xff, 
    0xe0, 0x07, 0xff, 0xfc, 0x7f, 0xff, 0xe0, 0x07, 0xff, 0xfc, 0x00, 0x00, 0x00, 0x3f, 0xff, 0xe0, 
    0x03, 0xff, 0xfc, 0x7f, 0xff, 0xe0, 0x07, 0xff, 0xfc, 0x00, 0x00, 0x00, 0x3f, 0xff, 0xe0, 0x01, 
    0xff, 0x4c, 0x3f, 0xff, 0xe0, 0x07, 0xff, 0xfe, 0x00, 0x00, 0x00, 0x7f, 0xff, 0xe0, 0x00, 0x00, 
    0x48, 0x3f, 0xff, 0xf0, 0x03, 0xff, 0xff, 0x00, 0x00, 0x00, 0xff, 0xff, 0xc0, 0x04, 0x00, 0x00, 
    0x1f, 0xff, 0xf0, 0x01, 0xff, 0xff, 0x00, 0x00, 0x00, 0xff, 0xff, 0x80, 0x02, 0x00, 0x10, 0x0f, 
    0xff, 0xf8, 0x01, 0xff, 0xff, 0x80, 0x00, 0x01, 0xff, 0xff, 0x80, 0x09, 0x00, 0x40, 0x0f, 0xff, 
    0xfc, 0x00, 0xff, 0xff, 0x80, 0x00, 0x01, 0xff, 0xff, 0x00, 0x18, 0x00, 0x40, 0x07, 0xff, 0xfc, 
    0x00, 0xff, 0xff, 0xc0, 0x00, 0x03, 0xff, 0xff, 0x00, 0x16, 0x00, 0x00, 0x07, 0xff, 0xfe, 0x00, 
    0x7f, 0xff, 0xc0, 0x00, 0x03, 0xff, 0xfe, 0x00, 0x10, 0x00, 0x00, 0x03, 0xff, 0xfe, 0x00, 0x7f, 
    0xff, 0xe0, 0x00, 0x07, 0xff, 0xfe, 0x00, 0x00, 0x01, 0x80, 0x03, 0xff, 0xff, 0x00, 0x3f, 0xff, 
    0xf0, 0x00, 0x0f, 0xff, 0xfc, 0x00, 0x64, 0x01, 0x00, 0x01, 0xff, 0xff, 0x80, 0x1f, 0xff, 0xf0, 
    0x00, 0x0f, 0xff, 0xf8, 0x00, 0x01, 0x01, 0x00, 0x00, 0xff, 0xff, 0x80, 0x1f, 0xff, 0xf8, 0x00, 
    0x1f, 0xff, 0xf8, 0x00, 0x00, 0x46, 0x00, 0x00, 0xff, 0xff, 0xc0, 0x0f, 0xff, 0xf8, 0x00, 0x1f, 
    0xff, 0xf0, 0x00, 0x80, 0x0c, 0x00, 0x00, 0x7f, 0xff, 0xc0, 0x0f, 0xff, 0xfc, 0x00, 0x3f, 0xff, 
    0xf0, 0x00, 0x08, 0x04, 0x00, 0x00, 0x7f, 0xff, 0xe0, 0x07, 0xff, 0xfe, 0x00, 0x7f, 0xff, 0xe0, 
    0x02, 0x00, 0x54, 0x00, 0x00, 0x3f, 0xff, 0xe0, 0x03, 0xff, 0xfe, 0x00, 0x7f, 0xff, 0xe0, 0x02, 
    0x00, 0x50, 0x00, 0x00, 0x1f, 0xff, 0xf0, 0x00, 0x00, 0x00, 0x00, 0xff, 0xff, 0xc0, 0x06, 0x00, 
    0x10, 0x00, 0x00, 0x1f, 0xff, 0xf8, 0x00, 0x00, 0x00, 0x00, 0xff, 0xff, 0x80, 0x00, 0x00, 0x00, 
    0x00, 0x00, 0x0f, 0xff, 0xf8, 0x00, 0x00, 0x00, 0x01, 0xff, 0xff, 0x80, 0x09, 0x80, 0x00, 0x00, 
    0x00, 0x0f, 0xff, 0xfc, 0x00, 0x00, 0x00, 0x03, 0xff, 0xff, 0x00, 0x11, 0x48, 0x80, 0x00, 0x00, 
    0x07, 0xff, 0xfc, 0x00, 0x00, 0x00, 0x03, 0xff, 0xfe, 0x00, 0x13, 0x42, 0x40, 0x00, 0x00, 0x07, 
    0xff, 0xfe, 0x00, 0x00, 0x00, 0x07, 0xff, 0xfe, 0x00, 0x32, 0x86, 0x00, 0x00, 0x00, 0x03, 0xff, 
    0xfe, 0x00, 0x00, 0x00, 0x07, 0xff, 0xfc, 0x00, 0x00, 0x00, 0x80, 0x00, 0x00, 0x01, 0xff, 0xff, 
    0x00, 0x00, 0x00, 0x0f, 0xff, 0xfc, 0x00, 0x04, 0x01, 0x00, 0x00, 0x00, 0x01, 0xff, 0xff, 0xff, 
    0xff, 0xff, 0xff, 0xff, 0xf8, 0x00, 0x84, 0x01, 0x00, 0x00, 0x00, 0x00, 0xff, 0xff, 0xff, 0xff, 
    0xff, 0xff, 0xff, 0xf8, 0x00, 0xa0, 0x12, 0x00, 0x00, 0x00, 0x00, 0xff, 0xff, 0xff, 0xff, 0xff, 
    0xff, 0xff, 0xf0, 0x01, 0x08, 0x12, 0x00, 0x00, 0x00, 0x00, 0x7f, 0xff, 0xff, 0xff, 0xff, 0xff, 
    0xff, 0xf0, 0x00, 0x00, 0xa0, 0x00, 0x00, 0x00, 0x00, 0x7f, 0xff, 0xff, 0xff, 0xff, 0xff, 0xff, 
    0xe0, 0x02, 0x00, 0x00, 0x00, 0x00, 0x00, 0x00, 0x3f, 0xff, 0xff, 0xff, 0xff, 0xff, 0xff, 0xc0, 
    0x02, 0x00, 0x08, 0x00, 0x00, 0x00, 0x00, 0x1f, 0xff, 0xff, 0xff, 0xff, 0xff, 0xff, 0xc0, 0x00, 
    0x00, 0x00, 0x00, 0x00, 0x00, 0x00, 0x1f, 0xff, 0xff, 0xff, 0xff, 0xff, 0xff, 0x80, 0x01, 0x00, 
    0x00, 0x00, 0x00, 0x00, 0x00, 0x0f, 0xff, 0xff, 0xff, 0xff, 0xff, 0xff, 0x80, 0x01, 0x00, 0x20, 
    0x00, 0x00, 0x00, 0x00, 0x0f, 0xff, 0xff, 0xff, 0xff, 0xff, 0xff, 0x00, 0x00, 0x00, 0x40, 0x00, 
    0x00, 0x00, 0x00, 0x07, 0xff, 0xff, 0xff, 0xff, 0xff, 0xfe, 0x00, 0x08, 0x00, 0xc0, 0x00, 0x00, 
    0x00, 0x00, 0x03, 0xff, 0xff, 0xff, 0xff, 0xff, 0xfe, 0x00, 0x20, 0x00, 0x80, 0x00, 0x00, 0x00, 
    0x00, 0x03, 0xff, 0xff, 0xff, 0xff, 0xff, 0xfc, 0x00, 0x26, 0x00, 0x00, 0x00, 0x00, 0x00, 0x00, 
    0x01, 0xff, 0xff, 0xff, 0xff, 0xff, 0xfc, 0x00, 0x7d, 0xff, 0x00, 0x00, 0x00, 0x00, 0x00, 0x00, 
    0xff, 0xff, 0xff, 0xff, 0xff, 0xf8, 0x00, 0x00, 0x00, 0x00, 0x00, 0x00, 0x00, 0x00, 0x00, 0x00, 
    0x00, 0x00, 0x00, 0x00, 0x00, 0x00, 0x00, 0x00, 0x00, 0x00, 0x00, 0x00, 0x00, 0x00, 0x00, 0x00, 
    0x00, 0x00, 0x00, 0x00, 0x00, 0x00, 0x00, 0x00, 0x00, 0x00, 0x00, 0x00, 0x00, 0x00, 0x00, 0x00, 
    0x00, 0x00, 0x00, 0x00, 0x00, 0x00, 0x00, 0x00, 0x00, 0x00, 0x00, 0x00, 0x00, 0x00, 0x00, 0x00, 
    0x00, 0x08, 0x00, 0x00, 0x00, 0x00, 0x00, 0x00, 0x7e, 0x00, 0x18, 0x00, 0x04, 0x0c, 0x00, 0x20, 
    0x7f, 0x00, 0x40, 0x00, 0x40, 0x00, 0x00, 0x7e, 0x00, 0x1c, 0x00, 0x0e, 0x0c, 0x00, 0x60, 0x77, 
    0x00, 0x60, 0x1c, 0x40, 0x00, 0x00, 0x7c, 0x7f, 0xdf, 0xbe, 0x7e, 0xfd, 0xf3, 0xe0, 0x7f, 0x3e, 
    0x68, 0xde, 0x4f, 0x9f, 0x3e, 0x7e, 0x6c, 0xd8, 0xff, 0xe7, 0xcd, 0xfe, 0x60, 0x7f, 0x63, 0xe8, 
    0xd8, 0x48, 0xd9, 0xbe, 0xfe, 0xe4, 0x59, 0xbe, 0xe7, 0xcd, 0xf6, 0x60, 0x63, 0x73, 0x6d, 0xdf, 
    0x4d, 0xd1, 0xbf, 0x7e, 0x44, 0x5f, 0x9e, 0x7c, 0xf9, 0xf3, 0xe0, 0x7f, 0x3e, 0x4f, 0x8e, 0x4f, 
    0x91, 0x3e, 0x00, 0x00, 0x00, 0x00, 0x00, 0x00, 0x00, 0x00, 0x00, 0x00, 0x00, 0x00, 0x00, 0x00, 
    0x00, 0x00, 0x00, 0x00, 0x00, 0x00, 0x00, 0x00, 0x00, 0x00, 0x00, 0x00, 0x00, 0x00, 0x00, 0x00, 
    0x00, 0x00, 0x00, 0x00, 0x00, 0x00, 0x00, 0x00, 0x00, 0x00, 0x00, 0x00, 0x00, 0x00, 0x00, 0x00, 
    0x00, 0x00, 0x00, 0x00, 0x00, 0x00, 0x00, 0x00, 0x00, 0x00, 0x00, 0x00, 0x00, 0x00, 0x00, 0x00, 
    0x00, 0x00, 0x00, 0x00, 0x00, 0x00, 0x00, 0x00, 0x00, 0x00, 0x00, 0x00, 0x00, 0x00, 0x00, 0x00, 
    0x00, 0x00, 0x00, 0x00, 0x00, 0x00, 0x00, 0x00, 0x00, 0x00, 0x00, 0x00, 0x00, 0x00, 0x00, 0x00, 
    0x00, 0x00, 0x00, 0x00, 0x00, 0x00, 0x00, 0x00, 0x00, 0x00, 0x00, 0x00, 0x00, 0x00, 0x00, 0x00, 
    0x00, 0x00, 0x00, 0x00, 0x00, 0x00, 0x00, 0x00, 0x00, 0x00, 0x00, 0x00, 0x00, 0x00, 0x00, 0x00, 
    0x00, 0x00, 0x00, 0x00, 0x00, 0x00, 0x00, 0x00, 0x00, 0x00, 0x00, 0x00, 0x00, 0x00, 0x00, 0x00, 
    0x00, 0x00, 0x00, 0x00, 0x00, 0x00, 0x00, 0x00
};


const Image mab_labs = {
    .width = MY_IMAGE_WIDTH,
    .height = MY_IMAGE_HEIGHT,
    .data = mab_labs_data,
    .bytes_per_row = MY_IMAGE_BYTES_PER_ROW,
};
```

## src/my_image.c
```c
#include "images.h"

#define MY_IMAGE_WIDTH 73
#define MY_IMAGE_HEIGHT 100
#define MY_IMAGE_BYTES_PER_ROW ((MY_IMAGE_WIDTH + 7) / 8)
#define MY_IMAGE_DATA_SIZE (MY_IMAGE_BYTES_PER_ROW * MY_IMAGE_HEIGHT)

const uint8_t my_image_data[MY_IMAGE_DATA_SIZE] = {
// 'ken_chung', 73x100px
0x00, 0x00, 0x00, 0x00, 0x00, 0x00, 0x00, 0x00, 0x00, 0x00, 0x00, 0x00, 0x00, 0x00, 0x00, 0x00, 
0x00, 0x00, 0x00, 0x00, 0x00, 0x00, 0x00, 0x00, 0x00, 0x00, 0x00, 0x00, 0x00, 0x00, 0x00, 0x00, 
0x00, 0x00, 0x00, 0x00, 0x00, 0x00, 0x00, 0x00, 0x00, 0x00, 0x00, 0x00, 0x00, 0x00, 0x00, 0x00, 
0x00, 0x00, 0x00, 0x00, 0x00, 0x00, 0x00, 0x00, 0x00, 0x00, 0x00, 0x00, 0x00, 0x00, 0x00, 0x00, 
0x00, 0x00, 0x00, 0x00, 0x00, 0x00, 0x00, 0x00, 0x00, 0x00, 0x00, 0x00, 0x00, 0x00, 0x00, 0x00, 
0x00, 0x00, 0x00, 0x00, 0x00, 0x00, 0x00, 0x00, 0x00, 0x00, 0x00, 0x00, 0x00, 0x00, 0x00, 0x00, 
0x00, 0x00, 0x00, 0x00, 0x00, 0x00, 0x00, 0x00, 0x00, 0x00, 0x00, 0x00, 0x00, 0x00, 0x00, 0x00, 
0x00, 0x00, 0x00, 0x00, 0x00, 0x00, 0x00, 0x00, 0x00, 0x00, 0x00, 0x00, 0x00, 0x00, 0x00, 0x00, 
0x00, 0x00, 0x00, 0x00, 0x00, 0x00, 0x00, 0x00, 0x00, 0x00, 0x00, 0x00, 0x00, 0x00, 0x00, 0x00, 
0xe0, 0x00, 0x00, 0x00, 0x00, 0x00, 0x00, 0x00, 0x00, 0x07, 0xe0, 0x00, 0x00, 0x00, 0x00, 0x00, 
0x00, 0x00, 0x00, 0x0f, 0xe0, 0x00, 0x00, 0x00, 0x00, 0x00, 0x00, 0x00, 0x00, 0x0e, 0x30, 0x00, 
0x00, 0x00, 0x00, 0x00, 0x00, 0x00, 0x00, 0x00, 0x10, 0x00, 0x00, 0x00, 0x00, 0x00, 0x00, 0x00, 
0x00, 0x01, 0x11, 0xe0, 0x00, 0x00, 0x00, 0x00, 0x00, 0x00, 0x06, 0x0f, 0xff, 0xfe, 0x00, 0x00, 
0x00, 0x00, 0x00, 0x00, 0x07, 0x9f, 0xff, 0xff, 0x00, 0x00, 0x00, 0x00, 0x00, 0x00, 0x05, 0xff, 
0xff, 0xff, 0x00, 0x00, 0x00, 0x00, 0x00, 0x00, 0x03, 0xff, 0xff, 0xfe, 0x00, 0x00, 0x00, 0x00, 
0x00, 0x00, 0x07, 0xff, 0xf7, 0xfc, 0x00, 0x00, 0x00, 0x00, 0x00, 0x00, 0x0f, 0xff, 0xf7, 0xfc, 
0x00, 0x00, 0x00, 0x00, 0x00, 0x00, 0x0f, 0xff, 0xe3, 0xf9, 0x80, 0x00, 0x00, 0x00, 0x00, 0x00, 
0x1f, 0xff, 0xe1, 0xf0, 0x80, 0x00, 0x00, 0x00, 0x00, 0x00, 0x3f, 0x1f, 0xc0, 0xc0, 0x00, 0x00, 
0x00, 0x00, 0x00, 0x00, 0x1f, 0x1f, 0xc8, 0x70, 0x00, 0x00, 0x00, 0x00, 0x00, 0x00, 0x1e, 0x3f, 
0xbf, 0xfc, 0x00, 0x00, 0x00, 0x00, 0x00, 0x00, 0x1e, 0x3f, 0xff, 0xfe, 0x00, 0x00, 0x00, 0x00, 
0x00, 0x00, 0x0e, 0x7f, 0xff, 0x3e, 0x00, 0x00, 0x00, 0x00, 0x00, 0x00, 0x0f, 0xff, 0xfe, 0x3f, 
0x00, 0x00, 0x00, 0x00, 0x00, 0x00, 0x01, 0xff, 0xff, 0xff, 0x00, 0x00, 0x00, 0x00, 0x00, 0x00, 
0x01, 0xff, 0xff, 0xff, 0x00, 0x00, 0x00, 0x00, 0x00, 0x00, 0x01, 0xff, 0xf0, 0x7f, 0x00, 0x00, 
0x00, 0x00, 0x00, 0x00, 0x03, 0xff, 0xff, 0x7f, 0x00, 0x00, 0x00, 0x00, 0x00, 0x00, 0x01, 0xff, 
0xf0, 0x3e, 0x00, 0x00, 0x00, 0x00, 0x00, 0x00, 0x00, 0xff, 0xff, 0x3e, 0x00, 0x00, 0x00, 0x00, 
0x00, 0x00, 0x00, 0xff, 0xff, 0xfc, 0x00, 0x00, 0x00, 0x00, 0x00, 0x00, 0x00, 0xff, 0xff, 0x9c, 
0x00, 0x00, 0x00, 0x00, 0x00, 0x00, 0x00, 0x3f, 0xfe, 0x08, 0x00, 0x00, 0x00, 0x00, 0x00, 0x00, 
0x00, 0x3f, 0xfc, 0x10, 0x00, 0x00, 0x00, 0x00, 0x00, 0x00, 0x00, 0x5f, 0xff, 0x00, 0x00, 0x00, 
0x00, 0x00, 0x00, 0x00, 0x00, 0x5e, 0x7f, 0x80, 0x00, 0x00, 0x00, 0x00, 0x00, 0x00, 0x00, 0x3f, 
0xbf, 0x00, 0x00, 0x00, 0x00, 0x00, 0x00, 0x00, 0x00, 0x3f, 0xff, 0x84, 0x00, 0x00, 0x00, 0x00, 
0x00, 0x00, 0x00, 0x1f, 0xff, 0x06, 0x00, 0x00, 0x00, 0x00, 0x00, 0x00, 0x00, 0x0f, 0xff, 0x06, 
0x00, 0x00, 0x00, 0x00, 0x00, 0x00, 0x00, 0x0f, 0xff, 0x02, 0x00, 0x00, 0x00, 0x00, 0x00, 0x00, 
0x00, 0x07, 0xfe, 0x04, 0x00, 0x00, 0x00, 0x00, 0x00, 0x00, 0x00, 0x03, 0xfe, 0x08, 0x00, 0x00, 
0x00, 0x00, 0x00, 0x00, 0x00, 0x01, 0xfe, 0x18, 0x00, 0x00, 0x00, 0x00, 0x00, 0x00, 0x00, 0x00, 
0xfe, 0x20, 0x00, 0x00, 0x00, 0x00, 0x00, 0x00, 0x00, 0x00, 0x7f, 0xc0, 0x00, 0x00, 0x00, 0x00, 
0x00, 0x00, 0x00, 0x00, 0x04, 0x00, 0x00, 0x00, 0x00, 0x00, 0x00, 0x00, 0x00, 0x00, 0x00, 0x00, 
0x00, 0x00, 0x00, 0x00, 0x00, 0x00, 0x00, 0x00, 0x00, 0x00, 0x00, 0x00, 0x00, 0x00, 0x00, 0x00, 
0x00, 0x00, 0x00, 0x00, 0x00, 0x00, 0x00, 0x00, 0x00, 0x00, 0x00, 0x00, 0x00, 0x00, 0x00, 0x00, 
0x00, 0x00, 0x00, 0x00, 0x00, 0x00, 0x00, 0x00, 0x00, 0x00, 0x00, 0x00, 0x00, 0x00, 0x00, 0x00, 
0x00, 0x00, 0x00, 0x00, 0x00, 0x00, 0x00, 0x00, 0x00, 0x00, 0x00, 0x00, 0x00, 0x00, 0x00, 0x00, 
0x00, 0x00, 0x00, 0x00, 0x00, 0x00, 0x00, 0x00, 0x00, 0x00, 0x00, 0x00, 0x00, 0x00, 0x00, 0x00, 
0x00, 0x00, 0x00, 0x00, 0x00, 0x00, 0x00, 0x00, 0x00, 0x00, 0x00, 0x00, 0x00, 0x00, 0x00, 0x00, 
0x00, 0x00, 0x00, 0x00, 0x00, 0x00, 0x00, 0x00, 0x00, 0x00, 0x00, 0x00, 0x00, 0x00, 0x00, 0x00, 
0x00, 0x00, 0x00, 0x00, 0x00, 0x00, 0x00, 0x00, 0x00, 0x00, 0x00, 0x00, 0x00, 0x00, 0x00, 0x00, 
0x00, 0x00, 0x00, 0x00, 0x00, 0x00, 0x00, 0x00, 0x00, 0x00, 0x00, 0x00, 0x00, 0x00, 0x00, 0x00, 
0x00, 0x00, 0x00, 0x00, 0x00, 0x00, 0x00, 0x00, 0x00, 0x00, 0x00, 0x00, 0x00, 0x00, 0x00, 0x00, 
0x00, 0x00, 0x00, 0x00, 0x00, 0x00, 0x00, 0x00, 0x00, 0x00, 0x00, 0x00, 0x00, 0x00, 0x00, 0x00, 
0x00, 0x00, 0x00, 0x00, 0x00, 0x00, 0x00, 0x00, 0x00, 0x00, 0x00, 0x00, 0x00, 0x00, 0x00, 0x00, 
0x00, 0x00, 0x00, 0x00, 0x00, 0x00, 0x00, 0x00, 0x00, 0x00, 0x00, 0x00, 0x00, 0x00, 0x00, 0x00, 
0x00, 0x00, 0x00, 0x00, 0x00, 0x00, 0x00, 0x00, 0x00, 0x00, 0x00, 0x00, 0x00, 0x00, 0x00, 0x00, 
0x00, 0x00, 0x00, 0x00, 0x00, 0x00, 0x00, 0x00, 0x00, 0x00, 0x01, 0x00, 0x00, 0x00, 0x00, 0x00, 
0x00, 0x00, 0x00, 0x00, 0xe1, 0x00, 0x00, 0x00, 0x00, 0x00, 0x00, 0x00, 0x00, 0x00, 0xf9, 0x00, 
0x00, 0x00, 0x00, 0x00, 0x00, 0x00, 0x00, 0x00, 0xf9, 0x04, 0x00, 0x00, 0x00, 0x00, 0x00, 0x00, 
0x00, 0x00, 0xf9, 0x88, 0x20, 0x00, 0x00, 0x00, 0x00, 0x00, 0x00, 0x00, 0xff, 0xc8, 0xc0, 0x00, 
0x00, 0x00, 0x00, 0x00, 0x00, 0x00, 0xff, 0xff, 0x80, 0x00, 0x00, 0x00, 0x00, 0x00, 0x00, 0x00, 
0xff, 0xfe, 0x00, 0x00, 0x00, 0x00, 0x00, 0x00, 0x00, 0x00, 0xff, 0xfc, 0x00, 0x00, 0x00, 0x00, 
0x00, 0x00, 0x00, 0x00, 0xff, 0xf8, 0x00, 0x00, 0x00, 0x00, 0x00, 0x00, 0x00, 0x00, 0xff, 0xf0, 
0x00, 0x00, 0x00, 0x00, 0x00, 0x00, 0x00, 0x00, 0xff, 0xf0, 0x00, 0x00, 0x00, 0x00, 0x00, 0x00, 
0x00, 0x00, 0xff, 0xe0, 0x00, 0x00, 0x00, 0x00, 0x00, 0x00, 0x00, 0x00, 0xff, 0xe0, 0x00, 0x00, 
0x00, 0x00, 0x00, 0x00, 0x00, 0x00, 0xff, 0xe0, 0x00, 0x00, 0x00, 0x00, 0x00, 0x00, 0x00, 0x00, 
0xff, 0xc0, 0x00, 0x00, 0x00, 0x00, 0x00, 0x00, 0x00, 0x00, 0xff, 0xc0, 0x00, 0x00, 0x00, 0x00, 
0x00, 0x00, 0x00, 0x00, 0xff, 0xc8, 0x07, 0x80, 0x00, 0x00, 0x00, 0x00, 0x00, 0x00, 0xff, 0xcc, 
0x1f, 0x80, 0x00, 0x00, 0x00, 0x00, 0x00, 0x00
};

const Image my_image = {
    .width = MY_IMAGE_WIDTH,
    .height = MY_IMAGE_HEIGHT,
    .data = my_image_data,
    .bytes_per_row = MY_IMAGE_BYTES_PER_ROW,
};
```
